# FM33FG0XXA register map
File version: 1.0
CPU: SC000 r1p0, little endian, MPU, no FPU, 3 interrupt priority bits
Registers are 32-bit, read-only, reset 0x0 unless marked. A register's access mark holds for its fields unless they carry their own. Offsets are from the block's base; [hi:lo] are bit positions.

## LPUART0 — LPUART0 module information
Base 0x40014000
Same registers: LPUART1 0x40014400, LPUART2 0x40015000
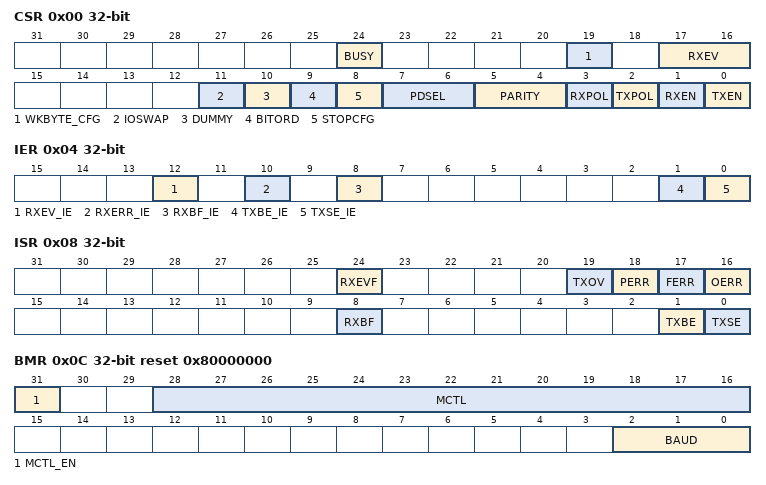
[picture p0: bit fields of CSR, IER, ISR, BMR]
0x00 CSR access per field — LPUART0 Control Status Register
  [24] BUSY ro — BUSY field description
  [19] WKBYTE_CFG rw — WKBYTE_CFG field description
  [17:16] RXEV rw — RXEV field description
  [11] IOSWAP rw — IOSWAP field description
  [10] DUMMY rw — DUMMY field description
  [9] BITORD rw — BITORD field description
  [8] STOPCFG rw — STOPCFG field description
  [7:6] PDSEL rw — PDSEL field description
  [5:4] PARITY rw — PARITY field description
  [3] RXPOL rw — RXPOL field description
  [2] TXPOL rw — TXPOL field description
  [1] RXEN rw — RXEN field description
  [0] TXEN rw — TXEN field description
0x04 IER rw — LPUART0 Interrupt Enable Register
  [12] RXEV_IE — RXEV_IE field description
  [10] RXERR_IE — RXERR_IE field description
  [8] RXBF_IE — RXBF_IE field description
  [1] TXBE_IE — TXBE_IE field description
  [0] TXSE_IE — TXSE_IE field description
0x08 ISR rw — LPUART0 Interrupt Status Register
  [24] RXEVF — RXEVF field description
  [19] TXOV — TXOV field description
  [18] PERR — PERR field description
  [17] FERR — FERR field description
  [16] OERR — OERR field description
  [8] RXBF — RXBF field description
  [1] TXBE — TXBE field description
  [0] TXSE — TXSE field description
0x0C BMR rw reset 0x80000000 — LPUART0 Baud rate Modulation Register
  [31] MCTL_EN — MCTL_EN field description
  [28:16] MCTL — MCTL field description
  [2:0] BAUD — BAUD field description
0x10 RXBUF — LPUART0 Receive Buffer Register
  [8:0] RXBUF — RXBUF field description
0x14 TXBUF rw — LPUART0 Transmit Buffer Register
  [8:0] TXBUF — TXBUF field description
0x18 DMR rw — LPUART0 data Matching Register
  [8:0] MATD — MATD field description

## SPI0 — SPI0 module information
Base 0x40010400
Same registers: SPI1 0x40010800, SPI2 0x40014800, SPI3 0x4001A800
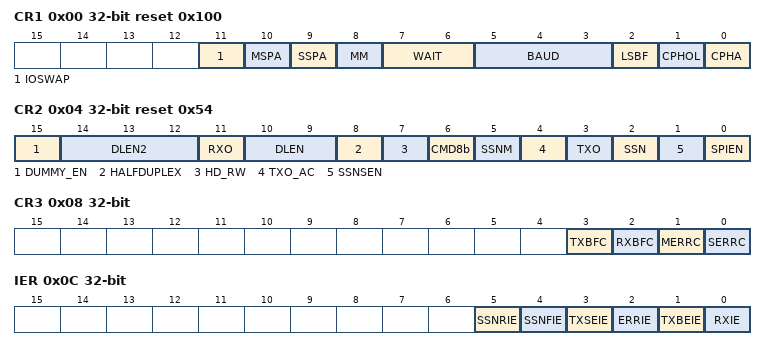
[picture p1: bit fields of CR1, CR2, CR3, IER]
0x00 CR1 rw reset 0x100 — SPI0 Control Register1
  [11] IOSWAP — IOSWAP field description
  [10] MSPA — MSPA field description
  [9] SSPA — SSPA field description
  [8] MM — MM field description
  [7:6] WAIT — WAIT field description
  [5:3] BAUD — BAUD field description
  [2] LSBF — LSBF field description
  [1] CPHOL — CPHOL field description
  [0] CPHA — CPHA field description
0x04 CR2 rw reset 0x54 — SPI0 Control Register2
  [15] DUMMY_EN — DUMMY_EN field description
  [14:12] DLEN2 — DLEN2 field description
  [11] RXO — RXO field description
  [10:9] DLEN — DLEN field description
  [8] HALFDUPLEX — HALFDUPLEX field description
  [7] HD_RW — HD_RW field description
  [6] CMD8b — CMD8b field description
  [5] SSNM — SSNM field description
  [4] TXO_AC — TXO_AC field description
  [3] TXO — TXO field description
  [2] SSN — SSN field description
  [1] SSNSEN — SSNSEN field description
  [0] SPIEN — SPIEN field description
0x08 CR3 rw — SPI0 Control Register3
  [3] TXBFC — TXBFC field description
  [2] RXBFC — RXBFC field description
  [1] MERRC — MERRC field description
  [0] SERRC — SERRC field description
0x0C IER rw — SPI0 Interrupt Enable Register
  [5] SSNRIE — SSNRIE field description
  [4] SSNFIE — SSNFIE field description
  [3] TXSEIE — TXSEIE field description
  [2] ERRIE — ERRIE field description
  [1] TXBEIE — TXBEIE field description
  [0] RXIE — RXIE field description
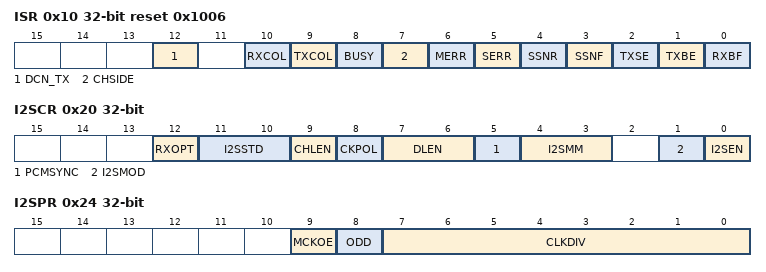
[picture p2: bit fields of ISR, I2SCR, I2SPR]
0x10 ISR access per field reset 0x1006 — SPI0 Status Register
  [12] DCN_TX rw — DCN_TX field description
  [10] RXCOL rw — RXCOL field description
  [9] TXCOL rw — TXCOL field description
  [8] BUSY ro — BUSY field description
  [7] CHSIDE ro — CHSIDE field description
  [6] MERR rw — MERR field description
  [5] SERR rw — SERR field description
  [4] SSNR rw — SSNR field description
  [3] SSNF rw — SSNF field description
  [2] TXSE ro — TXSE field description
  [1] TXBE ro — TXBE field description
  [0] RXBF ro — RXBF field description
0x14 TXBUF wo — SPI0 Transmit Buffer
  [31:0] TXBUF — TXBUF field description
0x18 RXBUF — SPI0 Receive Buffer
  [31:0] RXBUF — RXBUF field description
0x20 I2SCR rw — SPI0 I2S Control Register
  [12] RXOPT — RXOPT field description
  [11:10] I2SSTD — I2SSTD field description
  [9] CHLEN — CHLEN field description
  [8] CKPOL — CKPOL field description
  [7:6] DLEN — DLEN field description
  [5] PCMSYNC — PCMSYNC field description
  [4:3] I2SMM — I2SMM field description
  [1] I2SMOD — I2SMOD field description
  [0] I2SEN — I2SEN field description
0x24 I2SPR rw — SPI0 I2S Prescaler Register
  [9] MCKOE — MCKOE field description
  [8] ODD — ODD field description
  [7:0] CLKDIV — CLKDIV field description
